# MSP432P401Y register map
Vendor: Texas Instruments; File version: 3.230
Registers are 32-bit, read-write, reset 0x0 unless marked. A register's access mark holds for its fields unless they carry their own. Offsets are from the block's base; [hi:lo] are bit positions; {n}, {i} and the like mark numbered series; 'fields as' and 'values as' point back to an identical list.

## SystemControlSpace — System Control Space for ARM core: SCnSCB, SCB, SysTick, NVIC, CoreDebug, MPU, FPU
Base 0xE000E000
0x04 ICTR ro — Interrupt Control Type Register
  [4:0] INTLINESNUM — Total number of interrupt lines in groups of 32.
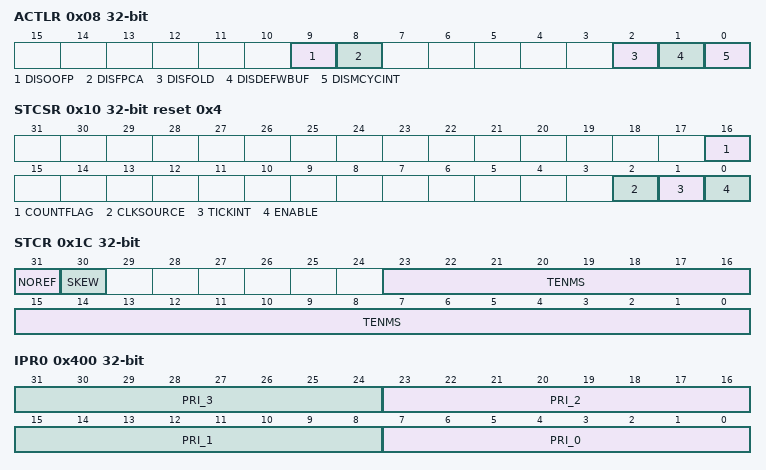
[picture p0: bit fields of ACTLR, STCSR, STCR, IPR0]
0x08 ACTLR — Auxiliary Control Register
  [9] DISOOFP — Disables floating point instructions completing out of order with respect to integer instructions.
  [8] DISFPCA — Disable automatic update of CONTROL.FPCA
  [2] DISFOLD — Disables IT folding.
  [1] DISDEFWBUF — Disables write buffer us during default memorty map accesses. This causes all bus faults to be precise bus faults but decreases the performance of the processor because the stores to memory have to complete before the next instruction can be executed.
  [0] DISMCYCINT — Disables interruption of multi-cycle instructions. This increases the interrupt latency of the processor becuase LDM/STM completes before interrupt stacking occurs.
0x10 STCSR reset 0x4 — SysTick Control and Status Register
  [16] COUNTFLAG ro — Returns 1 if timer counted to 0 since last time this was read. Clears on read by application of any part of the SysTick Control and Status Register. If read by the debugger using the DAP, this bit is cleared on read-only if the MasterType bit in the AHB-AP Control Register is set to 0. Otherwise, the COUNTFLAG bit is not changed by the debugger read.
  [2] CLKSOURCE ro — Clock source.
    on read: 0=Not applicable; 1=Core clock
  [1] TICKINT
    0=Counting down to zero does not pend the SysTick handler. Software can use COUNTFLAG to determine if the SysTick handler has ever counted to zero.; 1=Counting down to zero pends the SysTick handler
  [0] ENABLE — Enable SysTick counter
    0=First (Counter disabled)
0x14 STRVR reset not defined — SysTick Reload Value Register
  [23:0] RELOAD — Value to load into the SysTick Current Value Register when the counter reaches 0.
0x18 STCVR reset not defined — SysTick Current Value Register
  [23:0] CURRENT — Current value at the time the register is accessed. No read-modify-write protection is provided, so change with care. Writing to it with any value clears the register to 0. Clearing this register also clears the COUNTFLAG bit of the SysTick Control and Status Register.
0x1C STCR ro reset not defined — SysTick Calibration Value Register
  [31] NOREF — Reads as one. Indicates that no separate reference clock is provided.
  [30] SKEW — Reads as one. The calibration value is not exactly 10ms because of clock frequency. This could affect its suitability as a software real time clock.
  [23:0] TENMS — Reads as zero. Indicates calibration value is not known.
0x100 ISER0 — Irq 0 to 31 Set Enable Register
  [31:0] SETENA — Writing 0 to a SETENA bit has no effect, writing 1 to a bit enables the corresponding interrupt. Reading the bit returns its current enable state. Reset clears the SETENA fields.
0x104 ISER1 — Irq 32 to 63 Set Enable Register
  fields as ISER0
0x180 ICER0 — Irq 0 to 31 Clear Enable Register
  [31:0] CLRENA — Writing 0 to a CLRENA bit has no effect, writing 1 to a bit disables the corresponding interrupt. Reading the bit returns its current enable state. Reset clears the CLRENA field.
0x184 ICER1 — Irq 32 to 63 Clear Enable Register
  fields as ICER0
0x200 ISPR0 — Irq 0 to 31 Set Pending Register
  [31:0] SETPEND — Writing 0 to a SETPEND bit has no effect, writing 1 to a bit pends the corresponding interrupt. Reading the bit returns its current state.
0x204 ISPR1 — Irq 32 to 63 Set Pending Register
  fields as ISPR0
0x280 ICPR0 — Irq 0 to 31 Clear Pending Register
  [31:0] CLRPEND — Writing 0 to a CLRPEND bit has no effect, writing 1 to a bit clears the corresponding pending interrupt. Reading the bit returns its current state.
0x284 ICPR1 — Irq 32 to 63 Clear Pending Register
  fields as ICPR0
0x300 IABR0 ro — Irq 0 to 31 Active Bit Register
  [31:0] ACTIVE — Interrupt active flags. Reading 0 implies the interrupt is not active or stacked. Reading 1 implies the interrupt is active or pre-empted and stacked.
0x304 IABR1 ro — Irq 32 to 63 Active Bit Register
  fields as IABR0
0x400 IPR0 — Irq 0 to 3 Priority Register
  [8n+7:8n] PRI_{n} (n=0..3) — Priority of interrupt {n}
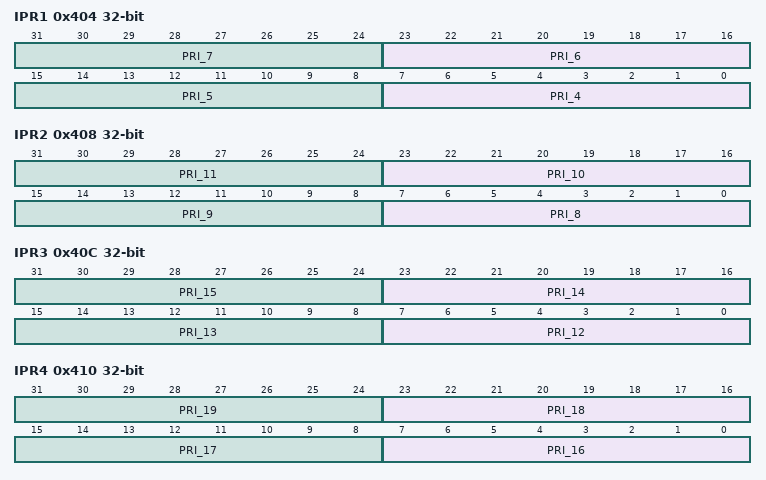
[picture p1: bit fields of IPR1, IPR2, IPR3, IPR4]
0x404 IPR1 — Irq 4 to 7 Priority Register
  [8n-25:8n-32] PRI_{n} (n=4..7) — Priority of interrupt {n}
0x408 IPR2 — Irq 8 to 11 Priority Register
  [8n-57:8n-64] PRI_{n} (n=8..11) — Priority of interrupt {n}
0x40C IPR3 — Irq 12 to 15 Priority Register
  [8n-89:8n-96] PRI_{n} (n=12..15) — Priority of interrupt {n}
0x410 IPR4 — Irq 16 to 19 Priority Register
  [8n-121:8n-128] PRI_{n} (n=16..19) — Priority of interrupt {n}
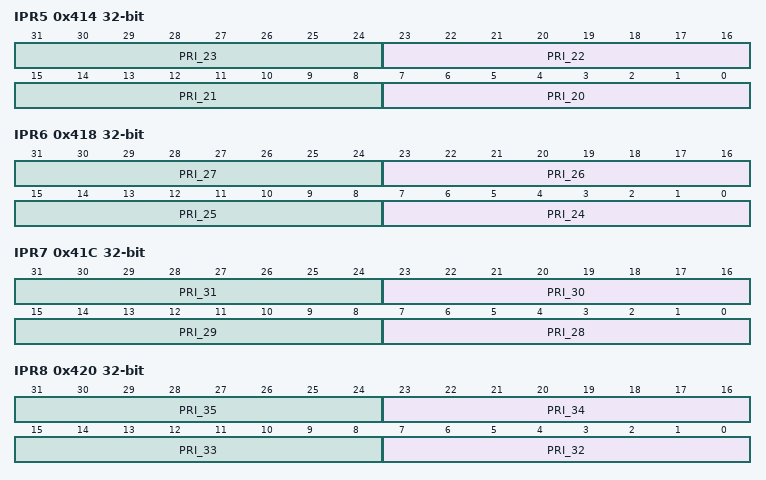
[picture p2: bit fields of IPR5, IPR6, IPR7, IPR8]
0x414 IPR5 — Irq 20 to 23 Priority Register
  [8n-153:8n-160] PRI_{n} (n=20..23) — Priority of interrupt {n}
0x418 IPR6 — Irq 24 to 27 Priority Register
  [8n-185:8n-192] PRI_{n} (n=24..27) — Priority of interrupt {n}
0x41C IPR7 — Irq 28 to 31 Priority Register
  [8n-217:8n-224] PRI_{n} (n=28..31) — Priority of interrupt {n}
0x420 IPR8 — Irq 32 to 35 Priority Register
  [8n-249:8n-256] PRI_{n} (n=32..35) — Priority of interrupt {n}
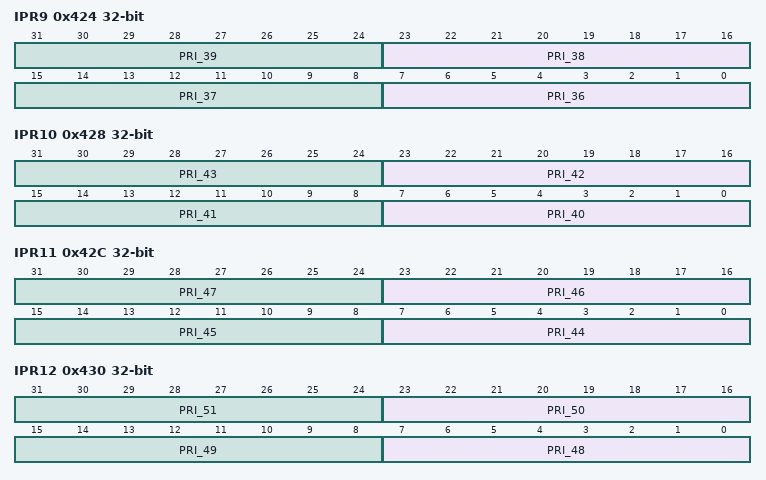
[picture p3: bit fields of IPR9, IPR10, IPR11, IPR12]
0x424 IPR9 — Irq 36 to 39 Priority Register
  [8n-281:8n-288] PRI_{n} (n=36..39) — Priority of interrupt {n}
0x428 IPR10 — Irq 40 to 43 Priority Register
  [8n-313:8n-320] PRI_{n} (n=40..43) — Priority of interrupt {n}
0x42C IPR11 — Irq 44 to 47 Priority Register
  [8n-345:8n-352] PRI_{n} (n=44..47) — Priority of interrupt {n}
0x430 IPR12 — Irq 48 to 51 Priority Register
  [8n-377:8n-384] PRI_{n} (n=48..51) — Priority of interrupt {n}
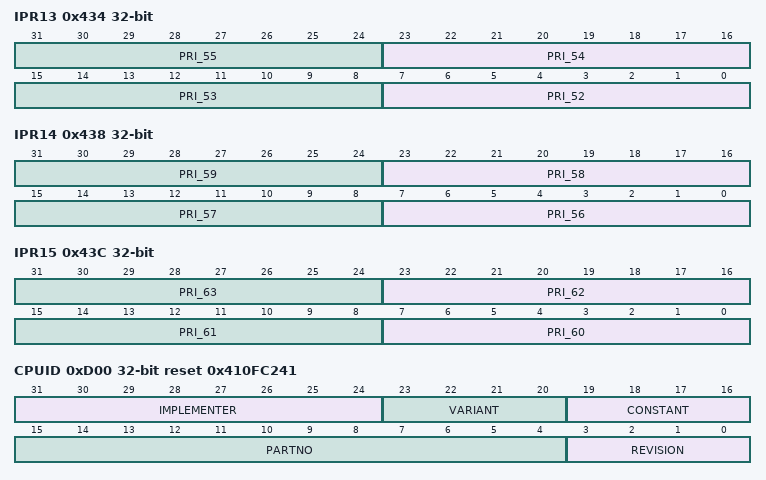
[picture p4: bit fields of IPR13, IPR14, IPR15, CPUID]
0x434 IPR13 — Irq 52 to 55 Priority Register
  [8n-409:8n-416] PRI_{n} (n=52..55) — Priority of interrupt {n}
0x438 IPR14 — Irq 56 to 59 Priority Register
  [8n-441:8n-448] PRI_{n} (n=56..59) — Priority of interrupt {n}
0x43C IPR15 — Irq 60 to 63 Priority Register
  [8n-473:8n-480] PRI_{n} (n=60..63) — Priority of interrupt {n}
0xD00 CPUID ro reset 0x410FC241 — CPUID Base Register
  [31:24] IMPLEMENTER — Implementor code.
  [23:20] VARIANT — Implementation defined variant number.
  [19:16] CONSTANT — Reads as 0xC
  [15:4] PARTNO — Number of processor within family.
  [3:0] REVISION — Implementation defined revision number.
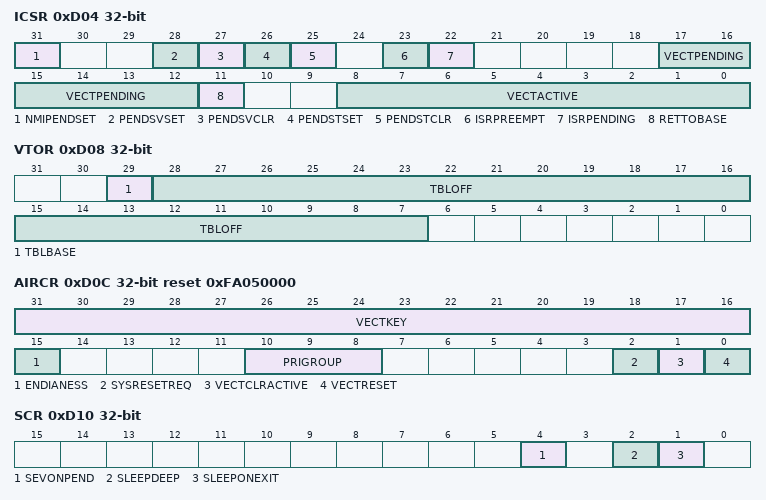
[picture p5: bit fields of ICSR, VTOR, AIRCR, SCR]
0xD04 ICSR — Interrupt Control State Register
  [31] NMIPENDSET — Set pending NMI bit. NMIPENDSET pends and activates an NMI. Because NMI is the highest-priority interrupt, it takes effect as soon as it registers.
    0=en_0b0 (do not set pending NMI); 1=en_0b1 (set pending NMI)
  [28] PENDSVSET — Set pending pendSV bit.
    0=en_0b0 (do not set pending pendSV); 1=en_0b1 (set pending PendSV)
  [27] PENDSVCLR wo — Clear pending pendSV bit
    0=en_0b0 (do not clear pending pendSV); 1=en_0b1 (clear pending pendSV)
  [26] PENDSTSET — Set a pending SysTick bit.
    0=en_0b0 (do not set pending SysTick); 1=en_0b1 (set pending SysTick)
  [25] PENDSTCLR wo — Clear pending SysTick bit
    0=en_0b0 (do not clear pending SysTick); 1=en_0b1 (clear pending SysTick)
  [23] ISRPREEMPT ro — You must only use this at debug time. It indicates that a pending interrupt is to be taken in the next running cycle. If C_MASKINTS is clear in the Debug Halting Control and Status Register, the interrupt is serviced.
    0=en_0b0 (a pending exception is not serviced.); 1=en_0b1 (a pending exception is serviced on exit from the debug halt state)
  [22] ISRPENDING ro — Interrupt pending flag. Excludes NMI and faults.
    0=en_0b0 (interrupt not pending); 1=en_0b1 (interrupt pending)
  [17:12] VECTPENDING ro — Pending ISR number field. VECTPENDING contains the interrupt number of the highest priority pending ISR.
  [11] RETTOBASE ro — This bit is 1 when the set of all active exceptions minus the IPSR_current_exception yields the empty set.
  [8:0] VECTACTIVE ro — Active ISR number field. Reset clears the VECTACTIVE field.
0xD08 VTOR — Vector Table Offset Register
  [29] TBLBASE — Table base is in Code (0) or RAM (1).
  [28:7] TBLOFF — Vector table base offset field. Contains the offset of the table base from the bottom of the SRAM or CODE space.
0xD0C AIRCR reset 0xFA050000 (reset mask 0xFFFF7FFF) — Application Interrupt/Reset Control Register
  [31:16] VECTKEY wo — Register key. Writing to this register requires 0x5FA in the VECTKEY field. Otherwise the write value is ignored.
  [15] ENDIANESS ro — Data endianness bit. ENDIANNESS is sampled from the BIGEND input port during reset. You cannot change ENDIANNESS outside of reset.
    0=en_0b0 (little endian); 1=en_0b1 (big endian)
  [10:8] PRIGROUP — Interrupt priority grouping field. The PRIGROUP field is a binary point position indicator for creating subpriorities for exceptions that share the same pre-emption level. It divides the PRI_n field in the Interrupt Priority Register into a pre-emption level and a subpriority level. The binary point is a left-of value. This means that the PRIGROUP value represents a point starting at the left of the Least Significant Bit (LSB). This is bit [0] of 7:0. The lowest value might not be 0 depending on the number of bits allocated for priorities, and implementation choices
  [2] SYSRESETREQ wo — Causes a signal to be asserted to the outer system that indicates a reset is requested. Intended to force a large system reset of all major components except for debug. Setting this bit does not prevent Halting Debug from running.
  [1] VECTCLRACTIVE wo — Clears all active state information for active NMI, fault, and interrupts. It is the responsibility of the application to reinitialize the stack. The VECTCLRACTIVE bit is for returning to a known state during debug. The VECTCLRACTIVE bit self-clears. IPSR is not cleared by this operation. So, if used by an application, it must only be used at the base level of activation, or within a system handler whose active bit can be set.
  [0] VECTRESET wo — System Reset bit. Resets the system, with the exception of debug components. The VECTRESET bit self-clears. Reset clears the VECTRESET bit. For debugging, only write this bit when the core is halted.
0xD10 SCR — System Control Register
  [4] SEVONPEND — When enabled, this causes WFE to wake up when an interrupt moves from inactive to pended. Otherwise, WFE only wakes up from an event signal, external and SEV instruction generated. The event input, RXEV, is registered even when not waiting for an event, and so effects the next WFE.
  [2] SLEEPDEEP — Sleep deep bit.
    0=en_0b0 (not OK to turn off system clock); 1=en_0b1 (indicates to the system that Cortex-M4 clock can be stopped. Setting this bit causes the SLEEPDEEP port to be asserted when the processor can be stopped.)
  [1] SLEEPONEXIT — Sleep on exit when returning from Handler mode to Thread mode. Enables interrupt driven applications to avoid returning to empty main application.
    0=en_0b0 (do not sleep when returning to thread mode); 1=en_0b1 (sleep on ISR exit)
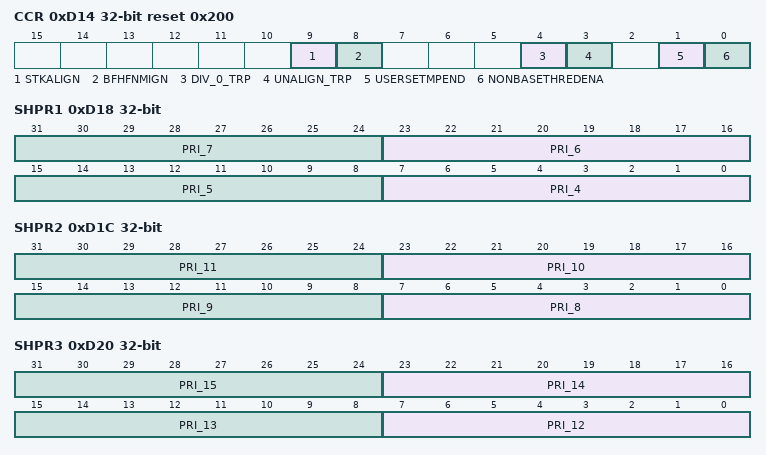
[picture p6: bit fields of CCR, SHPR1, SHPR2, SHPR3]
0xD14 CCR reset 0x200 — Configuration Control Register
  [9] STKALIGN — Stack alignment bit.
    0=en_0b0 (Only 4-byte alignment is guaranteed for the SP used prior to the exception on exception entry.); 1=en_0b1 (On exception entry, the SP used prior to the exception is adjusted to be 8-byte aligned and the context to restore it is saved. The SP is restored on the associated exception return.)
  [8] BFHFNMIGN — When enabled, this causes handlers running at priority -1 and -2 (Hard Fault, NMI, and FAULTMASK escalated handlers) to ignore Data Bus faults caused by load and store instructions. When disabled, these bus faults cause a lock-up. You must only use this enable with extreme caution. All data bus faults are ignored therefore you must only use it when the handler and its data are in absolutely safe memory. Its normal use is to probe system devices and bridges to detect control path problems and fix them.
  [4] DIV_0_TRP — Trap on Divide by 0. This enables faulting/halting when an attempt is made to divide by 0. The relevant Usage Fault Status Register bit is DIVBYZERO.
  [3] UNALIGN_TRP — Trap for unaligned access. This enables faulting/halting on any unaligned half or full word access. Unaligned load-store multiples always fault. The relevant Usage Fault Status Register bit is UNALIGNED.
  [1] USERSETMPEND — If written as 1, enables user code to write the Software Trigger Interrupt register to trigger (pend) a Main exception, which is one associated with the Main stack pointer.
  [0] NONBASETHREDENA — When 0, default, It is only possible to enter Thread mode when returning from the last exception. When set to 1, Thread mode can be entered from any level in Handler mode by controlled return value.
0xD18 SHPR1 — System Handlers 4-7 Priority Register
  [8n-25:8n-32] PRI_{n} (n=4..7) — Priority of system handler {n}.
0xD1C SHPR2 — System Handlers 8-11 Priority Register
  [8n-57:8n-64] PRI_{n} (n=8..11) — Priority of system handler {n}.
0xD20 SHPR3 — System Handlers 12-15 Priority Register
  [8n-89:8n-96] PRI_{n} (n=12..15) — Priority of system handler {n}.
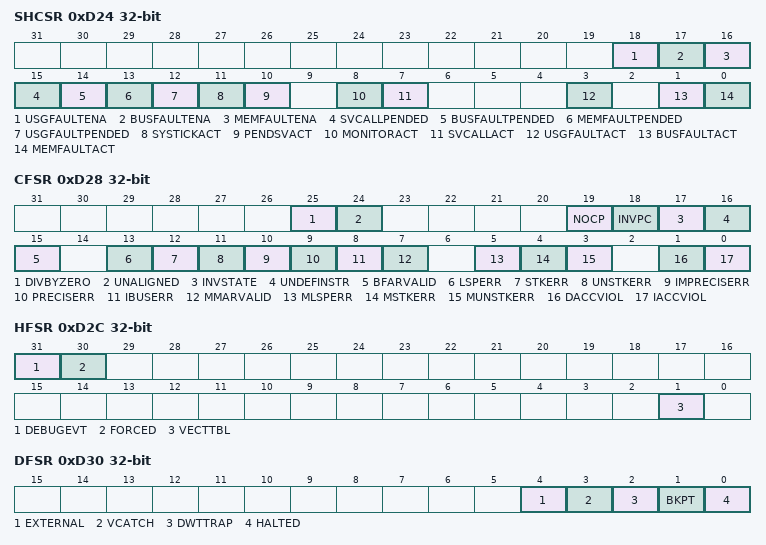
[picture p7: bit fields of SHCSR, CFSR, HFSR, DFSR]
0xD24 SHCSR — System Handler Control and State Register
  [18] USGFAULTENA — Usage fault system handler enable
    0=en_0b0 (disabled); 1=en_0b1 (enabled)
  [17] BUSFAULTENA — Bus fault system handler enable
    0=en_0b0 (disabled); 1=en_0b1 (enabled)
  [16] MEMFAULTENA — MemManage fault system handler enable
    0=en_0b0 (disabled); 1=en_0b1 (enabled)
  [15] SVCALLPENDED ro — SVCall pended flag.
    0=en_0b0 (not pended); 1=en_0b1 (pended)
  [14] BUSFAULTPENDED ro — BusFault pended flag.
    0=en_0b0 (not pended); 1=en_0b1 (pended)
  [13] MEMFAULTPENDED ro — MemManage pended flag.
    0=en_0b0 (not pended); 1=en_0b1 (pended)
  [12] USGFAULTPENDED ro — usage fault pended flag.
    0=en_0b0 (not pended); 1=en_0b1 (pended)
  [11] SYSTICKACT ro — SysTick active flag.
    0=en_0b0 (not active); 1=en_0b1 (active)
  [10] PENDSVACT ro — PendSV active flag.
    0=en_0b0 (not active); 1=en_0b1 (active)
  [8] MONITORACT ro — the Monitor active flag.
    0=en_0b0 (not active); 1=en_0b1 (active)
  [7] SVCALLACT ro — SVCall active flag.
    0=en_0b0 (not active); 1=en_0b1 (active)
  [3] USGFAULTACT ro — UsageFault active flag.
    0=en_0b0 (not active); 1=en_0b1 (active)
  [1] BUSFAULTACT ro — BusFault active flag.
    0=en_0b0 (not active); 1=en_0b1 (active)
  [0] MEMFAULTACT ro — MemManage active flag.
    0=en_0b0 (not active); 1=en_0b1 (active)
0xD28 CFSR — Configurable Fault Status Registers
  [25] DIVBYZERO — When DIV_0_TRP (see Configuration Control Register on page 8-26) is enabled and an SDIV or UDIV instruction is used with a divisor of 0, this fault occurs The instruction is executed and the return PC points to it. If DIV_0_TRP is not set, then the divide returns a quotient of 0.
  [24] UNALIGNED — When UNALIGN_TRP is enabled (see Configuration Control Register on page 8-26), and there is an attempt to make an unaligned memory access, then this fault occurs. Unaligned LDM/STM/LDRD/STRD instructions always fault irrespective of the setting of UNALIGN_TRP.
  [19] NOCP — Attempt to use a coprocessor instruction. The processor does not support coprocessor instructions.
  [18] INVPC — Attempt to load EXC_RETURN into PC illegally. Invalid instruction, invalid context, invalid value. The return PC points to the instruction that tried to set the PC.
  [17] INVSTATE — Invalid combination of EPSR and instruction, for reasons other than UNDEFINED instruction. Return PC points to faulting instruction, with the invalid state.
  [16] UNDEFINSTR — The UNDEFINSTR flag is set when the processor attempts to execute an undefined instruction. This is an instruction that the processor cannot decode. The return PC points to the undefined instruction.
  [15] BFARVALID — This bit is set if the Bus Fault Address Register (BFAR) contains a valid address. This is true after a bus fault where the address is known. Other faults can clear this bit, such as a Mem Manage fault occurring later. If a Bus fault occurs that is escalated to a Hard Fault because of priority, the Hard Fault handler must clear this bit. This prevents problems if returning to a stacked active Bus fault handler whose BFAR value has been overwritten.
  [13] LSPERR — Indicates if bus fault occurred during FP lazy state preservation.
  [12] STKERR — Stacking from exception has caused one or more bus faults. The SP is still adjusted and the values in the context area on the stack might be incorrect. The BFAR is not written.
  [11] UNSTKERR — Unstack from exception return has caused one or more bus faults. This is chained to the handler, so that the original return stack is still present. SP is not adjusted from failing return and new save is not performed. The BFAR is not written.
  [10] IMPRECISERR — Imprecise data bus error. It is a BusFault, but the Return PC is not related to the causing instruction. This is not a synchronous fault. So, if detected when the priority of the current activation is higher than the Bus Fault, it only pends. Bus fault activates when returning to a lower priority activation. If a precise fault occurs before returning to a lower priority exception, the handler detects both IMPRECISERR set and one of the precise fault status bits set at the same time. The BFAR is not written.
  [9] PRECISERR — Precise data bus error return.
  [8] IBUSERR — Instruction bus error flag. The IBUSERR flag is set by a prefetch error. The fault stops on the instruction, so if the error occurs under a branch shadow, no fault occurs. The BFAR is not written.
  [7] MMARVALID — Memory Manage Address Register (MMAR) address valid flag. A later-arriving fault, such as a bus fault, can clear a memory manage fault.. If a MemManage fault occurs that is escalated to a Hard Fault because of priority, the Hard Fault handler must clear this bit. This prevents problems on return to a stacked active MemManage handler whose MMAR value has been overwritten.
  [5] MLSPERR — Indicates if MemManage fault occurred during FP lazy state preservation.
  [4] MSTKERR — Stacking from exception has caused one or more access violations. The SP is still adjusted and the values in the context area on the stack might be incorrect. The MMAR is not written.
  [3] MUNSTKERR — Unstack from exception return has caused one or more access violations. This is chained to the handler, so that the original return stack is still present. SP is not adjusted from failing return and new save is not performed. The MMAR is not written.
  [1] DACCVIOL — Data access violation flag. Attempting to load or store at a location that does not permit the operation sets the DACCVIOL flag. The return PC points to the faulting instruction. This error loads MMAR with the address of the attempted access.
  [0] IACCVIOL — Instruction access violation flag. Attempting to fetch an instruction from a location that does not permit execution sets the IACCVIOL flag. This occurs on any access to an XN region, even when the MPU is disabled or not present. The return PC points to the faulting instruction. The MMAR is not written.
0xD2C HFSR — Hard Fault Status Register
  [31] DEBUGEVT — This bit is set if there is a fault related to debug. This is only possible when halting debug is not enabled. For monitor enabled debug, it only happens for BKPT when the current priority is higher than the monitor. When both halting and monitor debug are disabled, it only happens for debug events that are not ignored (minimally, BKPT). The Debug Fault Status Register is updated.
  [30] FORCED — Hard Fault activated because a Configurable Fault was received and cannot activate because of priority or because the Configurable Fault is disabled. The Hard Fault handler then has to read the other fault status registers to determine cause.
  [1] VECTTBL — This bit is set if there is a fault because of vector table read on exception processing (Bus Fault). This case is always a Hard Fault. The return PC points to the pre-empted instruction.
0xD30 DFSR — Debug Fault Status Register
  [4] EXTERNAL — External debug request flag. The processor stops on next instruction boundary.
    0=en_0b0 (EDBGRQ signal not asserted); 1=en_0b1 (EDBGRQ signal asserted)
  [3] VCATCH — Vector catch flag. When the VCATCH flag is set, a flag in one of the local fault status registers is also set to indicate the type of fault.
    0=en_0b0 (no vector catch occurred); 1=en_0b1 (vector catch occurred)
  [2] DWTTRAP — Data Watchpoint and Trace (DWT) flag. The processor stops at the current instruction or at the next instruction.
    0=en_0b0 (no DWT match); 1=en_0b1 (DWT match)
  [1] BKPT — BKPT flag. The BKPT flag is set by a BKPT instruction in flash patch code, and also by normal code. Return PC points to breakpoint containing instruction.
    0=en_0b0 (no BKPT instruction execution); 1=en_0b1 (BKPT instruction execution)
  [0] HALTED — Halt request flag. The processor is halted on the next instruction.
    0=en_0b0 (no halt request); 1=en_0b1 (halt requested by NVIC, including step)
0xD34 MMFAR reset not defined — Mem Manage Fault Address Register
  [31:0] ADDRESS — Mem Manage fault address field. ADDRESS is the data address of a faulted load or store attempt. When an unaligned access faults, the address is the actual address that faulted. Because an access can be split into multiple parts, each aligned, this address can be any offset in the range of the requested size. Flags in the Memory Manage Fault Status Register indicate the cause of the fault
0xD38 BFAR reset not defined — Bus Fault Address Register
  [31:0] ADDRESS — Bus fault address field. ADDRESS is the data address of a faulted load or store attempt. When an unaligned access faults, the address is the address requested by the instruction, even if that is not the address that faulted. Flags in the Bus Fault Status Register indicate the cause of the fault
0xD3C AFSR — Auxiliary Fault Status Register
  [31:0] IMPDEF — Implementation defined. The bits map directly onto the signal assignment to the AUXFAULT inputs.
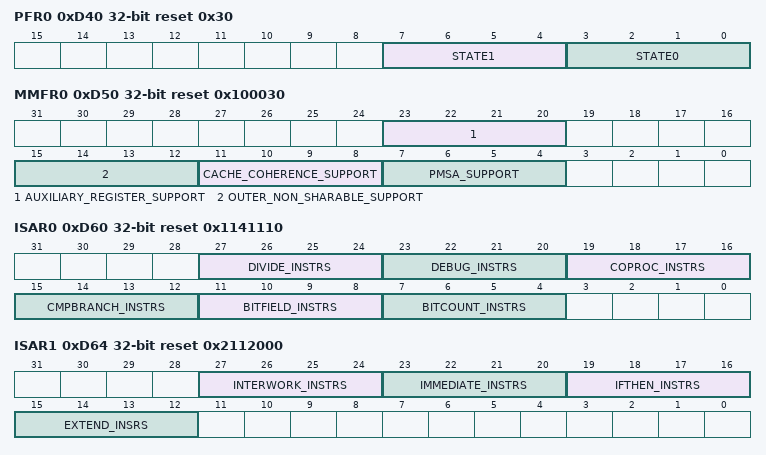
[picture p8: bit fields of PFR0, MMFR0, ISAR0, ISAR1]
0xD40 PFR0 ro reset 0x30 — Processor Feature register0
  [7:4] STATE1 — State1 (T-bit == 1)
    0=en_0b0000 (N/A); 1=en_0b0001 (N/A); 2=en_0b0010 (Thumb-2 encoding with the 16-bit basic instructions plus 32-bit Buncond/BL but no other 32-bit basic instructions (Note non-basic 32-bit instructions can be added using the appropriate instruction attribute, but other 32-bit basic instructions cannot.)); 3=en_0b0011 (Thumb-2 encoding with all Thumb-2 basic instructions)
  [3:0] STATE0 — State0 (T-bit == 0)
    0=en_0b0000 (no ARM encoding); 1=en_0b0001 (N/A)
0xD44 PFR1 ro reset 0x200 — Processor Feature register1
  [11:8] MICROCONTROLLER_PROGRAMMERS_MODEL
    0=en_0b0000 (not supported); 2=en_0b0010 (two-stack support)
0xD48 DFR0 ro reset 0x100000 — Debug Feature register0
  [23:20] MICROCONTROLLER_DEBUG_MODEL — Microcontroller Debug Model - memory mapped
    0=en_0b0000 (not supported); 1=en_0b0001 (Microcontroller debug v1 (ITMv1, DWTv1, optional ETM))
0xD4C AFR0 ro — Auxiliary Feature register0
0xD50 MMFR0 ro reset 0x100030 — Memory Model Feature register0
  [23:20] AUXILIARY_REGISTER_SUPPORT
    0=en_0b0000 (not supported); 1=en_0b0001 (Auxiliary control register)
  [15:12] OUTER_NON_SHARABLE_SUPPORT
    0=en_0b0000 (Outer non-sharable not supported); 1=en_0b0001 (Outer sharable supported)
  [11:8] CACHE_COHERENCE_SUPPORT
    0=en_0b0000 (no shared support); 1=en_0b0001 (partial-inner-shared coherency (coherency amongst some - but not all - of the entities within an inner-coherent domain)); 2=en_0b0010 (full-inner-shared coherency (coherency amongst all of the entities within an inner-coherent domain)); 3=en_0b0011 (full coherency (coherency amongst all of the entities))
  [7:4] PMSA_SUPPORT
    0=en_0b0000 (not supported); 1=en_0b0001 (IMPLEMENTATION DEFINED (N/A)); 2=en_0b0010 (PMSA base (features as defined for ARMv6) (N/A)); 3=en_0b0011 (PMSAv7 (base plus subregion support))
0xD54 MMFR1 ro — Memory Model Feature register1
0xD58 MMFR2 ro — Memory Model Feature register2
  [27:24] WAIT_FOR_INTERRUPT_STALLING
    0=en_0b0000 (not supported); 1=en_0b0001 (wait for interrupt supported)
0xD5C MMFR3 ro — Memory Model Feature register3
0xD60 ISAR0 ro reset 0x1141110 — ISA Feature register0
  [27:24] DIVIDE_INSTRS — Divide instructions
    0=en_0b0000 (no divide instructions present); 1=en_0b0001 (adds SDIV, UDIV (v1 quotient only result))
  [23:20] DEBUG_INSTRS — Debug instructions
    0=en_0b0000 (no debug instructions present); 1=en_0b0001 (adds BKPT)
  [19:16] COPROC_INSTRS — Coprocessor instructions
    0=en_0b0000 (no coprocessor support, other than for separately attributed architectures such as CP15 or VFP); 1=en_0b0001 (adds generic CDP, LDC, MCR, MRC, STC); 2=en_0b0010 (adds generic CDP2, LDC2, MCR2, MRC2, STC2); 3=en_0b0011 (adds generic MCRR, MRRC); 4=en_0b0100 (adds generic MCRR2, MRRC2)
  [15:12] CMPBRANCH_INSTRS — CmpBranch instructions
    0=en_0b0000 (no combined compare-and-branch instructions present); 1=en_0b0001 (adds CB{N}Z)
  [11:8] BITFIELD_INSTRS — BitField instructions
    0=en_0b0000 (no bitfield instructions present); 1=en_0b0001 (adds BFC, BFI, SBFX, UBFX)
  [7:4] BITCOUNT_INSTRS — BitCount instructions
    0=en_0b0000 (no bit-counting instructions present); 1=en_0b0001 (adds CLZ)
0xD64 ISAR1 ro reset 0x2112000 — ISA Feature register1
  [27:24] INTERWORK_INSTRS — Interwork instructions
    0=en_0b0000 (no interworking instructions supported); 1=en_0b0001 (adds BX (and T bit in PSRs)); 2=en_0b0010 (adds BLX, and PC loads have BX-like behavior); 3=en_0b0011 (N/A)
  [23:20] IMMEDIATE_INSTRS — Immediate instructions
    0=en_0b0000 (no special immediate-generating instructions present); 1=en_0b0001 (adds ADDW, MOVW, MOVT, SUBW)
  [19:16] IFTHEN_INSTRS — IfThen instructions
    0=en_0b0000 (IT instructions not present); 1=en_0b0001 (adds IT instructions (and IT bits in PSRs))
  [15:12] EXTEND_INSRS — Extend instructions. Note that the shift options on these instructions are also controlled by the WithShifts_instrs attribute.
    0=en_0b0000 (no scalar (i.e. non-SIMD) sign/zero-extend instructions present); 1=en_0b0001 (adds SXTB, SXTH, UXTB, UXTH); 2=en_0b0010 (N/A)
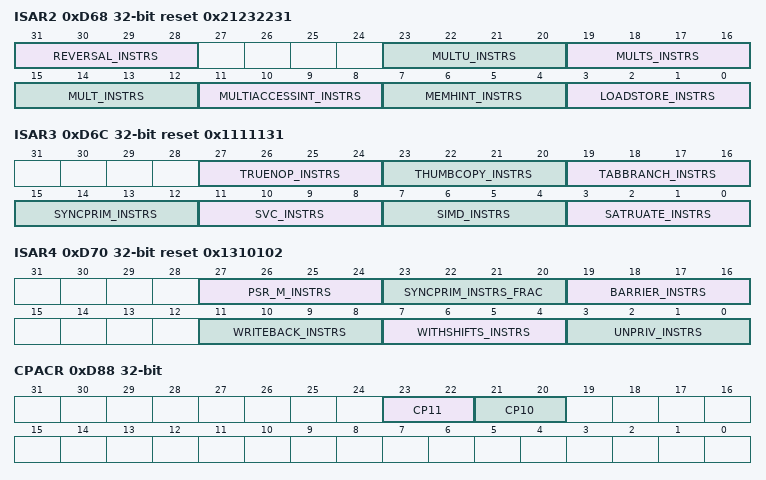
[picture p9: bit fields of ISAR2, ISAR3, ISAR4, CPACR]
0xD68 ISAR2 ro reset 0x21232231 — ISA Feature register2
  [31:28] REVERSAL_INSTRS — Reversal instructions
    0=en_0b0000 (no reversal instructions present); 1=en_0b0001 (adds REV, REV16, REVSH); 2=en_0b0010 (adds RBIT)
  [23:20] MULTU_INSTRS — Multiply instructions (advanced, unsigned)
    0=en_0b0000 (no unsigned multiply instructions present); 1=en_0b0001 (adds UMULL, UMLAL); 2=en_0b0010 (N/A)
  [19:16] MULTS_INSTRS — Multiply instructions (advanced, signed)
    0=en_0b0000 (no signed multiply instructions present); 1=en_0b0001 (adds SMULL, SMLAL); 2=en_0b0010 (N/A); 3=en_0b0011 (N/A)
  [15:12] MULT_INSTRS — Multiply instructions
    0=en_0b0000 (only MUL present); 1=en_0b0001 (adds MLA); 2=en_0b0010 (adds MLS)
  [11:8] MULTIACCESSINT_INSTRS — Multi-Access interruptible instructions
    0=en_0b0000 (the (LDM/STM) instructions are non-interruptible); 1=en_0b0001 (the (LDM/STM) instructions are restartable); 2=en_0b0010 (the (LDM/STM) instructions are continuable)
  [7:4] MEMHINT_INSTRS — MemoryHint instructions
    0=en_0b0000 (no memory hint instructions presen); 1=en_0b0001 (adds PLD); 2=en_0b0010 (adds PLD (ie a repeat on value 1)); 3=en_0b0011 (adds PLI)
  [3:0] LOADSTORE_INSTRS — LoadStore instructions
    0=en_0b0000 (no additional normal load/store instructions present); 1=en_0b0001 (adds LDRD/STRD)
0xD6C ISAR3 ro reset 0x1111131 — ISA Feature register3
  [27:24] TRUENOP_INSTRS — TrueNOP instructions
    0=en_0b0000 (true NOP instructions not present - that is, NOP instructions with no register dependencies); 1=en_0b0001 (adds "true NOP", and the capability of additional "NOP compatible hints")
  [23:20] THUMBCOPY_INSTRS — ThumbCopy instructions
    0=en_0b0000 (Thumb MOV(register) instruction does not allow low reg -> low reg); 1=en_0b0001 (adds Thumb MOV(register) low reg -> low reg and the CPY alias)
  [19:16] TABBRANCH_INSTRS — TableBranch instructions
    0=en_0b0000 (no table-branch instructions present); 1=en_0b0001 (adds TBB, TBH)
  [15:12] SYNCPRIM_INSTRS — SyncPrim instructions. Note there are no LDREXD or STREXD in ARMv7-M. This attribute is used in conjunction with the SyncPrim_instrs_frac attribute in ID_ISAR4[23:20].
    0=en_0b0000 (no synchronization primitives present); 1=en_0b0001 (adds LDREX, STREX); 2=en_0b0010 (adds LDREXB, LDREXH, LDREXD, STREXB, STREXH, STREXD, CLREX(N/A))
  [11:8] SVC_INSTRS — SVC instructions
    0=en_0b0000 (no SVC (SWI) instructions present); 1=en_0b0001 (adds SVC (SWI))
  [7:4] SIMD_INSTRS — SIMD instructions
    0=en_0b0000 (no SIMD instructions present); 1=en_0b0001 (adds SSAT, USAT (and the Q flag in the PSRs)); 3=en_0b0011 (N/A)
  [3:0] SATRUATE_INSTRS — Saturate instructions
    0=en_0b0000 (no non-SIMD saturate instructions present); 1=en_0b0001 (N/A)
0xD70 ISAR4 ro reset 0x1310102 — ISA Feature register4
  [27:24] PSR_M_INSTRS
    0=en_0b0000 (instructions not present); 1=en_0b0001 (adds CPS, MRS, and MSR instructions (M-profile forms))
  [23:20] SYNCPRIM_INSTRS_FRAC
    0=en_0b0000 (no additional support); 3=en_0b0011 (adds CLREX, LDREXB, STREXB, LDREXH, STREXH)
  [19:16] BARRIER_INSTRS — Barrier instructions
    0=en_0b0000 (no barrier instructions supported); 1=en_0b0001 (adds DMB, DSB, ISB barrier instructions)
  [11:8] WRITEBACK_INSTRS — Writeback instructions
    0=en_0b0000 (only non-writeback addressing modes present, except that LDMIA/STMDB/PUSH/POP instructions support writeback addressing.); 1=en_0b0001 (adds all currently-defined writeback addressing modes (ARMv7, Thumb-2))
  [7:4] WITHSHIFTS_INSTRS — WithShift instructions. Note that all additions only apply in cases where the encoding supports them - e.g. there is no difference between levels 3 and 4 in the Thumb-2 instruction set. Also note that MOV instructions with shift options should instead be treated as ASR, LSL, LSR, ROR or RRX instructions.
    0=en_0b0000 (non-zero shifts only support MOV and shift instructions (see notes)); 1=en_0b0001 (shifts of loads/stores over the range LSL 0-3); 3=en_0b0010 (adds other constant shift options.); 4=en_0b0100 (adds register-controlled shift options.)
  [3:0] UNPRIV_INSTRS — Unprivileged instructions
    0=en_0b0000 (no "T variant" instructions exist); 1=en_0b0001 (adds LDRBT, LDRT, STRBT, STRT); 2=en_0b0010 (adds LDRHT, LDRSBT, LDRSHT, STRHT)
0xD88 CPACR reset not defined — Coprocessor Access Control Register
  [23:22] CP11 — Access privileges for coprocessor 11. The possible values of each field are: 0b00 = Access denied. Any attempted access generates a NOCP UsageFault. 0b01 = Privileged access only. An unprivileged access generates a NOCP UsageFault. 0b10 = Reserved. 0b11 = Full access. Used in conjunction with the control for CP10, this controls access to the Floating Point Coprocessor.
  [21:20] CP10 — Access privileges for coprocessor 10. The possible values of each field are: 0b00 = Access denied. Any attempted access generates a NOCP UsageFault. 0b01 = Privileged access only. An unprivileged access generates a NOCP UsageFault. 0b10 = Reserved. 0b11 = Full access. Used in conjunction with the control for CP11, this controls access to the Floating Point Coprocessor.
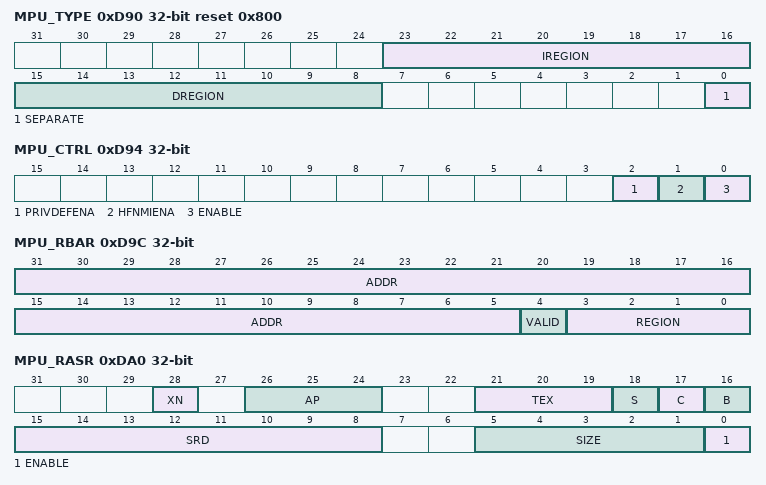
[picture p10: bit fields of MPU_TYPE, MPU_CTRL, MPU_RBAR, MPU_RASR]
0xD90 MPU_TYPE ro reset 0x800
  [23:16] IREGION — Because the processor core uses only a unified MPU, IREGION always contains 0x00.
  [15:8] DREGION — Number of supported MPU regions field. DREGION contains 0x08 if the implementation contains an MPU indicating eight MPU regions, otherwise it contains 0x00.
  [0] SEPARATE — Because the processor core uses only a unified MPU, SEPARATE is always 0.
0xD94 MPU_CTRL — MPU Control Register
  [2] PRIVDEFENA — This bit enables the default memory map for privileged access, as a background region, when the MPU is enabled. The background region acts as if it was region number 1 before any settable regions. Any region that is set up overlays this default map, and overrides it. If this bit = 0, the default memory map is disabled, and memory not covered by a region faults. This applies to memory type, Execute Never (XN), cache and shareable rules. However, this only applies to privileged mode (fetch and data access). User mode code faults unless a region has been set up for its code and data. When the MPU is disabled, the default map acts on both privileged and user mode code. XN and SO rules always apply to the System partition whether this enable is set or not. If the MPU is disabled, this bit is ignored. Reset clears the PRIVDEFENA bit.
  [1] HFNMIENA — This bit enables the MPU when in Hard Fault, NMI, and FAULTMASK escalated handlers. If this bit = 1 and the ENABLE bit = 1, the MPU is enabled when in these handlers. If this bit = 0, the MPU is disabled when in these handlers, regardless of the value of ENABLE. If this bit =1 and ENABLE = 0, behavior is Unpredictable. Reset clears the HFNMIENA bit.
  [0] ENABLE — MPU enable bit. Reset clears the ENABLE bit.
    0=en_0b0 (disable MPU); 1=en_0b1 (enable MPU)
0xD98 MPU_RNR reset not defined — MPU Region Number Register
  [7:0] REGION — Region select field. Selects the region to operate on when using the Region Attribute and Size Register and the Region Base Address Register. It must be written first except when the address VALID + REGION fields are written, which overwrites this.
0xD9C MPU_RBAR — MPU Region Base Address Register
  [31:5] ADDR — Region base address field. The position of the LSB depends on the region size, so that the base address is aligned according to an even multiple of size. The power of 2 size specified by the SZENABLE field of the MPU Region Attribute and Size Register defines how many bits of base address are used.
  [4] VALID — MPU Region Number valid bit.
    0=en_0b0 (MPU Region Number Register remains unchanged and is interpreted.); 1=en_0b1 (MPU Region Number Register is overwritten by bits 3:0 (the REGION value).)
  [3:0] REGION — MPU region override field.
0xDA0 MPU_RASR — MPU Region Attribute and Size Register
  [28] XN — Instruction access disable bit
    0=en_0b0 (enable instruction fetches); 1=en_0b1 (disable instruction fetches)
  [26:24] AP — Data access permission field
    0=en_0b000 (Priviliged permissions: No access. User permissions: No access.); 1=en_0b001 (Priviliged permissions: Read-write. User permissions: No access.); 2=en_0b010 (Priviliged permissions: Read-write. User permissions: Read-only.); 3=en_0b011 (Priviliged permissions: Read-write. User permissions: Read-write.); 5=en_0b101 (Priviliged permissions: Read-only. User permissions: No access.); 6=en_0b110 (Priviliged permissions: Read-only. User permissions: Read-only.); 7=en_0b111 (Priviliged permissions: Read-only. User permissions: Read-only.)
  [21:19] TEX — Type extension field
  [18] S — Shareable bit
    0=en_0b0 (not shareable); 1=en_0b1 (shareable)
  [17] C — Cacheable bit
    0=en_0b0 (not cacheable); 1=en_0b1 (cacheable)
  [16] B — Bufferable bit
    0=en_0b0 (not bufferable); 1=en_0b1 (bufferable)
  [15:8] SRD — Sub-Region Disable (SRD) field. Setting an SRD bit disables the corresponding sub-region. Regions are split into eight equal-sized sub-regions. Sub-regions are not supported for region sizes of 128 bytes and less.
  [5:1] SIZE — MPU Protection Region Size Field.
    4=en_0b00100 (32B); 5=en_0b00101 (64B); 6=en_0b00110 (128B); 7=en_0b00111 (256B); 8=en_0b01000 (512B); 9=en_0b01001 (1KB); 10=en_0b01010 (2KB); 11=en_0b01011 (4KB); 12=en_0b01100 (8KB); 13=en_0b01101 (16KB); 14=en_0b01110 (32KB); 15=en_0b01111 (64KB); 16=en_0b10000 (128KB); 17=en_0b10001 (256KB); 18=en_0b10010 (512KB); 19=en_0b10011 (1MB); 20=en_0b10100 (2MB); 21=en_0b10101 (4MB); 22=en_0b10110 (8MB); 23=en_0b10111 (16MB); 24=en_0b11000 (32MB); 25=en_0b11001 (64MB); 26=en_0b11010 (128MB); 27=en_0b11011 (256MB); 28=en_0b11100 (512MB); 29=en_0b11101 (1GB); 30=en_0b11110 (2GB); 31=en_0b11111 (4GB)
  [0] ENABLE — Region enable bit.
0xDA4 MPU_RBAR_A1 — MPU Alias 1 Region Base Address register
{0xDA0+8i} MPU_RASR_A{i} (i=1..3) — MPU Alias {i} Region Attribute and Size register
0xDAC MPU_RBAR_A2 — MPU Alias 2 Region Base Address register
0xDB4 MPU_RBAR_A3 reset not defined — MPU Alias 3 Region Base Address register
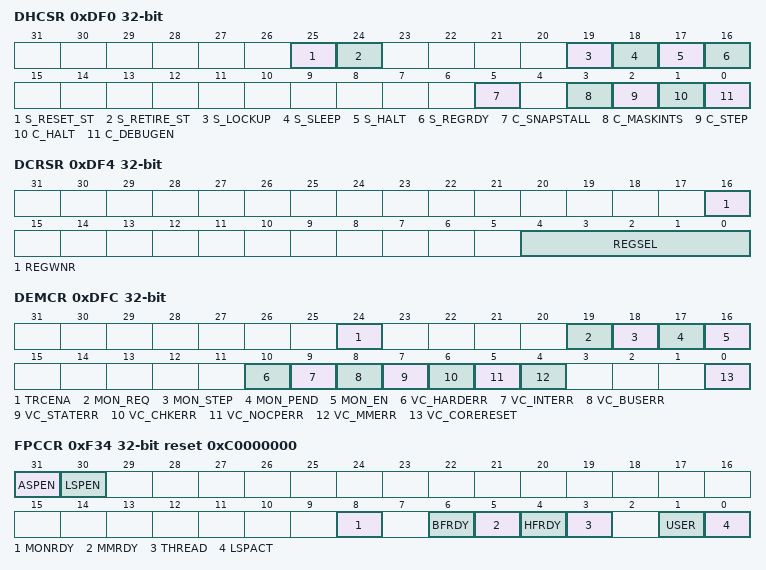
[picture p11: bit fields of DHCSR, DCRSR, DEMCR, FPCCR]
0xDF0 DHCSR (reset mask 0xFFFEFFFF) — Debug Halting Control and Status Register
  [25] S_RESET_ST ro — Indicates that the core has been reset, or is now being reset, since the last time this bit was read. This a sticky bit that clears on read. So, reading twice and getting 1 then 0 means it was reset in the past. Reading twice and getting 1 both times means that it is being reset now (held in reset still).
  [24] S_RETIRE_ST ro — Indicates that an instruction has completed since last read. This is a sticky bit that clears on read. This determines if the core is stalled on a load/store or fetch.
  [19] S_LOCKUP ro — Reads as one if the core is running (not halted) and a lockup condition is present.
  [18] S_SLEEP ro — Indicates that the core is sleeping (WFI, WFE, or SLEEP-ON-EXIT). Must use C_HALT to gain control or wait for interrupt to wake-up.
  [17] S_HALT ro — The core is in debug state when S_HALT is set.
  [16] S_REGRDY ro — Register Read/Write on the Debug Core Register Selector register is available. Last transfer is complete.
  [5] C_SNAPSTALL — If the core is stalled on a load/store operation the stall ceases and the instruction is forced to complete. This enables Halting debug to gain control of the core. It can only be set if: C_DEBUGEN = 1 and C_HALT = 1. The core reads S_RETIRE_ST as 0. This indicates that no instruction has advanced. This prevents misuse. The bus state is Unpredictable when this is used. S_RETIRE can detect core stalls on load/store operations.
  [3] C_MASKINTS — Mask interrupts when stepping or running in halted debug. Does not affect NMI, which is not maskable. Must only be modified when the processor is halted (S_HALT == 1). Also does not affect fault exceptions and SVC caused by execution of the instructions. CMASKINTS must be set or cleared before halt is released. This means that the writes to set or clear C_MASKINTS and to set or clear C_HALT must be separate.
  [2] C_STEP — Steps the core in halted debug. When C_DEBUGEN = 0, this bit has no effect. Must only be modified when the processor is halted (S_HALT == 1).
  [1] C_HALT — Halts the core. This bit is set automatically when the core Halts. For example Breakpoint. This bit clears on core reset. This bit can only be written if C_DEBUGEN is 1, otherwise it is ignored. When setting this bit to 1, C_DEBUGEN must also be written to 1 in the same value (value[1:0] is 2'b11). The core can halt itself, but only if C_DEBUGEN is already 1 and only if it writes with b11).
  [0] C_DEBUGEN — Enables debug. This can only be written by AHB-AP and not by the core. It is ignored when written by the core, which cannot set or clear it. The core must write a 1 to it when writing C_HALT to halt itself.
0xDF4 DCRSR wo reset not defined — Deubg Core Register Selector Register
  [16] REGWNR — Write = 1, Read = 0
  [4:0] REGSEL — Register select
    0=en_0b00000 (R0); 1=en_0b00001 (R1); 2=en_0b00010 (R2); 3=en_0b00011 (R3); 4=en_0b00100 (R4); 5=en_0b00101 (R5); 6=en_0b00110 (R6); 7=en_0b00111 (R7); 8=en_0b01000 (R8); 9=en_0b01001 (R9); 10=en_0b01010 (R10); 11=en_0b01011 (R11); 12=en_0b01100 (R12); 13=en_0b01101 (Current SP); 14=en_0b01110 (LR); 15=en_0b01111 (DebugReturnAddress); 16=en_0b10000 (xPSR/flags, execution state information, and exception number); 17=en_0b10001 (MSP (Main SP)); 18=en_0b10010 (PSP (Process SP)); 20=en_0b10100 (CONTROL bits [31:24], FAULTMASK bits [23:16], BASEPRI bits [15:8], PRIMASK bits [7:0])
0xDF8 DCRDR reset not defined — Debug Core Register Data Register
0xDFC DEMCR — Debug Exception and Monitor Control Register
  [24] TRCENA — This bit must be set to 1 to enable use of the trace and debug blocks: Data Watchpoint and Trace (DWT), Instrumentation Trace Macrocell (ITM), Embedded Trace Macrocell (ETM), Trace Port Interface Unit (TPIU). This enables control of power usage unless tracing is required. The application can enable this, for ITM use, or use by a debugger. Note that if no debug or trace components are present in the implementation then it is not possible to set TRCENA.
  [19] MON_REQ — This enables the monitor to identify how it wakes up. This bit clears on a Core Reset.
    0=en_0b0 (woken up by debug exception.); 1=en_0b1 (woken up by MON_PEND)
  [18] MON_STEP — When MON_EN = 1, this steps the core. When MON_EN = 0, this bit is ignored. This is the equivalent to C_STEP. Interrupts are only stepped according to the priority of the monitor and settings of PRIMASK, FAULTMASK, or BASEPRI.
  [17] MON_PEND — Pend the monitor to activate when priority permits. This can wake up the monitor through the AHB-AP port. It is the equivalent to C_HALT for Monitor debug. This register does not reset on a system reset. It is only reset by a POR reset. Software in the reset handler or later, or by the DAP must enable the debug monitor.
  [16] MON_EN — Enable the debug monitor. When enabled, the System handler priority register controls its priority level. If disabled, then all debug events go to Hard fault. C_DEBUGEN in the Debug Halting Control and Statue register overrides this bit. Vector catching is semi-synchronous. When a matching event is seen, a Halt is requested. Because the processor can only halt on an instruction boundary, it must wait until the next instruction boundary. As a result, it stops on the first instruction of the exception handler. However, two special cases exist when a vector catch has triggered: 1. If a fault is taken during vectoring, vector read or stack push error, the halt occurs on the corresponding fault handler, for the vector error or stack push. 2. If a late arriving interrupt comes in during vectoring, it is not taken. That is, an implementation that supports the late arrival optimization must suppress it in this case.
  [10] VC_HARDERR — Debug trap on Hard Fault.
  [9] VC_INTERR — Debug Trap on interrupt/exception service errors. These are a subset of other faults and catches before BUSERR or HARDERR.
  [8] VC_BUSERR — Debug Trap on normal Bus error.
  [7] VC_STATERR — Debug trap on Usage Fault state errors.
  [6] VC_CHKERR — Debug trap on Usage Fault enabled checking errors.
  [5] VC_NOCPERR — Debug trap on Usage Fault access to Coprocessor that is not present or marked as not present in CAR register.
  [4] VC_MMERR — Debug trap on Memory Management faults.
  [0] VC_CORERESET — Reset Vector Catch. Halt running system if Core reset occurs.
0xF00 STIR wo — Software Trigger Interrupt Register
  [8:0] INTID — Interrupt ID field. Writing a value to the INTID field is the same as manually pending an interrupt by setting the corresponding interrupt bit in an Interrupt Set Pending Register.
0xF34 FPCCR reset 0xC0000000 — Floating Point Context Control Register
  [31] ASPEN — Automatic State Preservation ENable. When this bit is set is will cause bit [2] of the Special CONTROL register to be set (FPCA) on execution of a floating point instruction which results in the floating point state automatically being preserved on exception entry.
  [30] LSPEN — Lazy State Preservation ENable. When the processor performs a context save, space on the stack is reserved for the floating point state but it is not stacked until the new context performs a floating point operation.
  [8] MONRDY — Indicates whether the the software executing when the processor allocated the FP stack frame was able to set the DebugMonitor exception to pending.
  [6] BFRDY — Indicates whether the software executing when the processor allocated the FP stack frame was able to set the BusFault exception to pending.
  [5] MMRDY — Indicates whether the software executing when the processor allocated the FP stack frame was able to set the MemManage exception to pending.
  [4] HFRDY — Indicates whether the software executing when the processor allocated the FP stack frame was able to set the HardFault exception to pending.
  [3] THREAD — Indicates the processor mode was Thread when it allocated the FP stack frame.
  [1] USER — Indicates the privilege level of the software executing was User (Unpriviledged) when the processor allocated the FP stack frame.
  [0] LSPACT — Indicates whether Lazy preservation of the FP state is active.
0xF38 FPCAR — Floating-Point Context Address Register
  [30:2] ADDRESS — Holds the (double-word-aligned) location of the unpopulated floating-point register space allocated on an exception stack frame.
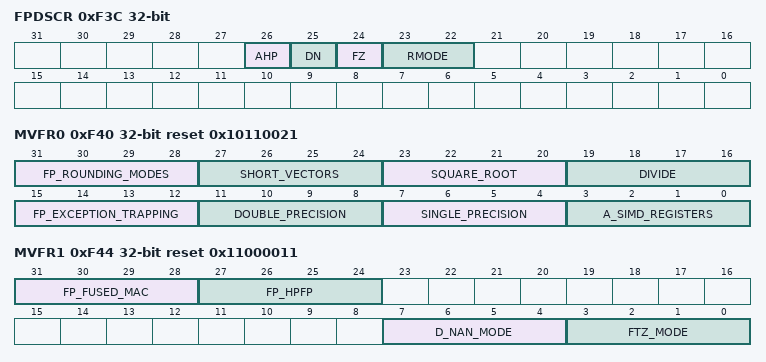
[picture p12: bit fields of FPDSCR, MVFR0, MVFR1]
0xF3C FPDSCR — Floating Point Default Status Control Register
  [26] AHP — Default value for Alternative Half Precision bit. (If this bit is set to 1 then Alternative half-precision format is selected).
  [25] DN — Default value for Default NaN mode bit. (If this bit is set to 1 then any operation involving one or more NaNs returns the Default NaN).
  [24] FZ — Default value for Flush-to-Zero mode bit. (If this bit is set to 1 then Flush-to-zero mode is enabled).
  [23:22] RMODE — Default value for Rounding Mode control field. (The encoding for this field is: 0b00 Round to Nearest (RN) mode, 0b01 Round towards Plus Infinity (RP) mode, 0b10 Round towards Minus Infinity (RM) mode, 0b11 Round towards Zero (RZ) mode. The specified rounding mode is used by almost all floating-point instructions).
0xF40 MVFR0 ro reset 0x10110021 — Media and FP Feature Register 0 (MVFR0)
  [31:28] FP_ROUNDING_MODES — Indicates the rounding modes supported by the FP floating-point hardware. The value of this field is: 0b0001 - all rounding modes supported.
  [27:24] SHORT_VECTORS — Indicates the hardware support for FP short vectors. The value of this field is: 0b0000 - not supported in ARMv7-M.
  [23:20] SQUARE_ROOT — Indicates the hardware support for FP square root operations. The value of this field is: 0b0001 - supported.
  [19:16] DIVIDE — Indicates the hardware support for FP divide operations. The value of this field is: 0b0001 - supported.
  [15:12] FP_EXCEPTION_TRAPPING — Indicates whether the FP hardware implementation supports exception trapping. The value of this field is: 0b0000 - not supported in ARMv7-M.
  [11:8] DOUBLE_PRECISION — Indicates the hardware support for FP double-precision operations. The value of this field is: 0b0000 - not supported in ARMv7-M.
  [7:4] SINGLE_PRECISION — Indicates the hardware support for FP single-precision operations. The value of this field is: 0b0010 - supported.
  [3:0] A_SIMD_REGISTERS — Indicates the size of the FP register bank. The value of this field is: 0b0001 - supported, 16 x 64-bit registers.
0xF44 MVFR1 ro reset 0x11000011 — Media and FP Feature Register 1 (MVFR1)
  [31:28] FP_FUSED_MAC — Indicates whether the FP supports fused multiply accumulate operations. The value of this field is: 0b0001 - supported.
  [27:24] FP_HPFP — Indicates whether the FP supports half-precision floating-point conversion operations. The value of this field is: 0b0001 - supported.
  [7:4] D_NAN_MODE — Indicates whether the FP hardware implementation supports only the Default NaN mode. The value of this field is: 0b0001 - hardware supports propagation of NaN values.
  [3:0] FTZ_MODE — Indicates whether the FP hardware implementation supports only the Flush-to-Zero mode of operation. The value of this field is: 0b0001 - hardware supports full denormalized number arithmetic.
